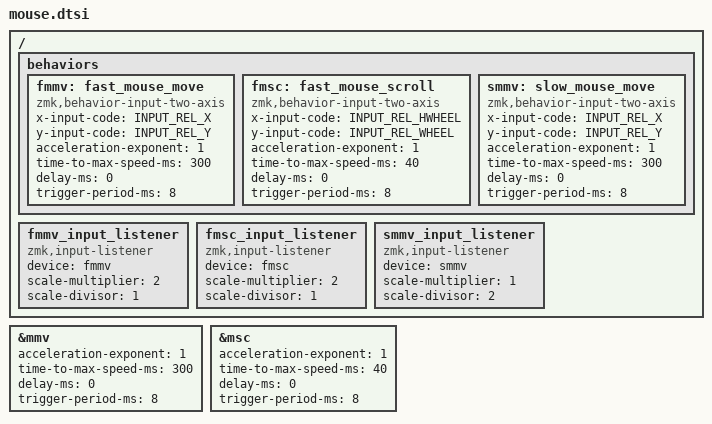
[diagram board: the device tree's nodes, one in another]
#define ZMK_MOUSE_DEFAULT_MOVE_VAL 800  // 600
#define ZMK_MOUSE_DEFAULT_SCRL_VAL 20   // 10

#include <dt-bindings/zmk/mouse.h>
#include <behaviors/mouse_keys.dtsi>

&mmv {
    acceleration-exponent = <1>;  // 1
    time-to-max-speed-ms = <300>; // 300
    delay-ms = <0>;
    trigger-period-ms = <8>;      // 16
};
&msc {
    acceleration-exponent = <1>;  // 0
    time-to-max-speed-ms = <40>;  // 300
    delay-ms = <0>;
    trigger-period-ms = <8>;      // 16
};

/ {
    behaviors {
        //  acceleration
        fmmv: fast_mouse_move {
            compatible = "zmk,behavior-input-two-axis";
            #binding-cells = <1>;
            x-input-code = <INPUT_REL_X>;
            y-input-code = <INPUT_REL_Y>;
            acceleration-exponent = <1>;  // 1
            time-to-max-speed-ms = <300>; // 300
            delay-ms = <0>;
            trigger-period-ms = <8>;      // 16
        };
        fmsc: fast_mouse_scroll {
            compatible = "zmk,behavior-input-two-axis";
            #binding-cells = <1>;
            x-input-code = <INPUT_REL_HWHEEL>;
            y-input-code = <INPUT_REL_WHEEL>;
            acceleration-exponent = <1>;  // 0
            time-to-max-speed-ms = <40>;  // 300
            delay-ms = <0>;
            trigger-period-ms = <8>;      // 16
        };
        //  deceleration
        smmv: slow_mouse_move {
            compatible = "zmk,behavior-input-two-axis";
            #binding-cells = <1>;
            x-input-code = <INPUT_REL_X>;
            y-input-code = <INPUT_REL_Y>;
            acceleration-exponent = <1>;  // 1
            time-to-max-speed-ms = <300>; // 300
            delay-ms = <0>;
            trigger-period-ms = <8>;      // 16
        };
    };
    
    //  acceleration
    fmmv_input_listener: fmmv_input_listener {
        compatible = "zmk,input-listener";
        device = <&fmmv>;
        scale-multiplier = <2>;
        scale-divisor = <1>;
    };
    fmsc_input_listener: fmsc_input_listener {
        compatible = "zmk,input-listener";
        device = <&fmsc>;
        scale-multiplier = <2>;
        scale-divisor = <1>;
    };
    //  deceleration
    smmv_input_listener: smmv_input_listener {
        compatible = "zmk,input-listener";
        device = <&smmv>;
        scale-multiplier = <1>;
        scale-divisor = <2>;
    };
};
